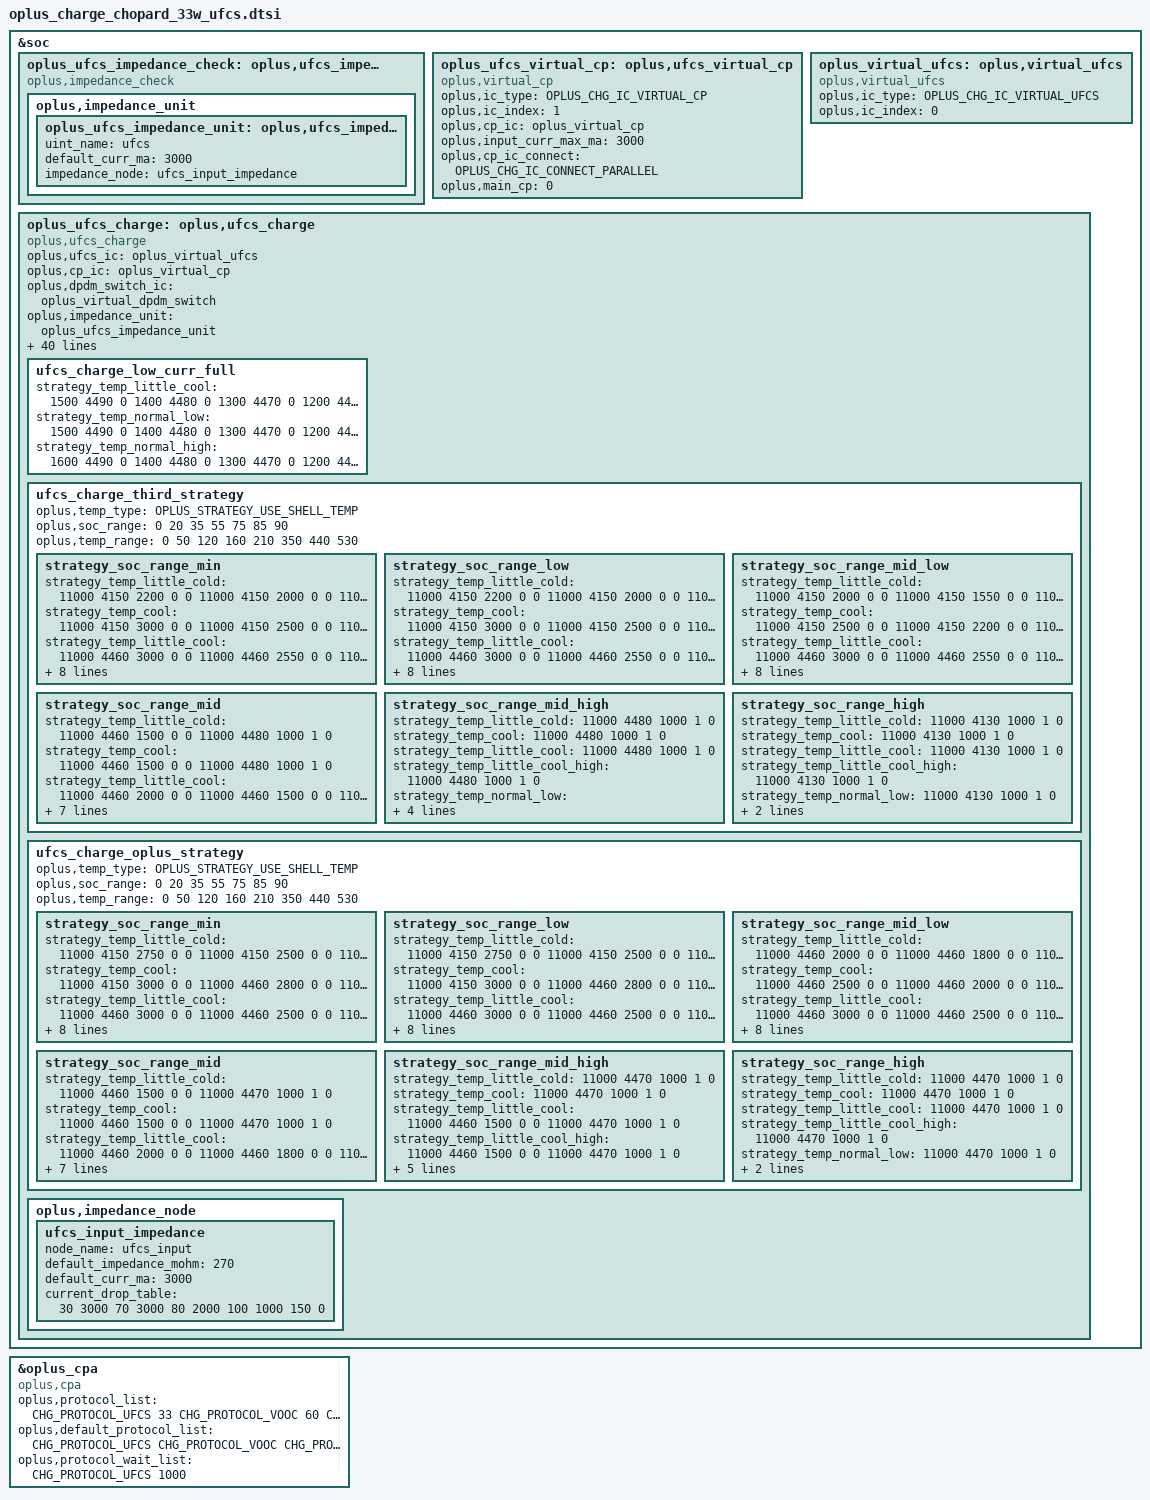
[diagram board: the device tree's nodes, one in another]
//ifdef OPLUS_FEATURE_CHG_BASIC

&soc {
	oplus_ufcs_impedance_check: oplus,ufcs_impedance_check {
		compatible = "oplus,impedance_check";

		oplus,impedance_unit {
			oplus_ufcs_impedance_unit: oplus,ufcs_impedance_unit {
				uint_name = "ufcs";
				default_curr_ma = <3000>;
				impedance_node = <&ufcs_input_impedance>;
			};
		};
	};

    oplus_ufcs_virtual_cp: oplus,ufcs_virtual_cp {
		compatible = "oplus,virtual_cp";

		oplus,ic_type = <OPLUS_CHG_IC_VIRTUAL_CP>;
		oplus,ic_index = <1>;

		oplus,cp_ic = <&oplus_virtual_cp>;
		oplus,input_curr_max_ma = <3000>;

		oplus,cp_ic_connect = <OPLUS_CHG_IC_CONNECT_PARALLEL>;
		oplus,main_cp = <0>;
	};

	oplus_virtual_ufcs: oplus,virtual_ufcs {
		compatible = "oplus,virtual_ufcs";

		oplus,ic_type = <OPLUS_CHG_IC_VIRTUAL_UFCS>;
		oplus,ic_index = <0>;
	};

	oplus_ufcs_charge: oplus,ufcs_charge {
		compatible = "oplus,ufcs_charge";
		oplus,ufcs_ic = <&oplus_virtual_ufcs>;
		oplus,cp_ic = <&oplus_virtual_cp>;
		oplus,dpdm_switch_ic = <&oplus_virtual_dpdm_switch>;

		oplus,impedance_unit = <&oplus_ufcs_impedance_unit>;

		oplus,target_vbus_mv = <11000>;
		oplus,curr_max_ma = <3000>;

		oplus,curr_table_type = <UFCS_CURR_CP_TABLE>;
		oplus,curve_strategy_name = "pps_ufcs_curve_v2";

		oplus,ufcs_warm_allow_vol = <4000>;
		oplus,ufcs_warm_allow_soc = <55>;
		oplus,ufcs_strategy_normal_current = <3000>;
		oplus,ufcs_over_high_or_low_current = <3000>;
		oplus,ufcs_timeout_third = <17562>;
		oplus,ufcs_timeout_oplus = <17562>;
		oplus,ufcs_ibat_over_third = <7000>;
		oplus,ufcs_ibat_over_oplus = <7000>;
		oplus,ufcs_full_cool_sw_vbat = <4470>;
		oplus,ufcs_full_normal_sw_vbat = <4520>;
		oplus,ufcs_full_normal_hw_vbat = <4530>;
		oplus,ufcs_full_ffc_vbat = <4485>;
		oplus,ufcs_full_warm_vbat = <4130>;
		oplus,ufcs_full_cool_sw_vbat_third = <4480>;
		oplus,ufcs_full_normal_sw_vbat_third= <4480>;
		oplus,ufcs_full_normal_hw_vbat_third = <4490>;
		oplus_spec,ufcs_high_soc = <86>;
		oplus,ufcs_current_change_timeout = <100>;
		oplus,ufcs_strategy_batt_high_temp = <410 420 430 400 410 420>;
		oplus,ufcs_strategy_high_current = <3000 2000 2000 3000 3000 3000>;
		oplus,ufcs_charge_strategy_soc = <0 20 35 55 75 85 90>;
		oplus,ufcs_charge_strategy_temp = <0 50 120 160 350 440 530>;
		oplus,ufcs_little_cool_high_temp = <210>;
		oplus,ufcs_low_curr_full_strategy_temp = <0 200 350 440>;

		oplus,plc_strategy-data = <&oplus_ufcs_step_strategy &third_ufcs_simple_strategy>;
		oplus,plc_strategy-names = "default", "third";

		oplus,temperature_strategy_name = "cgcl";
 		oplus,temperature_strategy_data = <OPLUS_STRATEGY_USE_SHELL_TEMP
 						0   410 4000 1 0
 						400 420 3000 2 0
						410 430 3000 3 1
 						420 440 2000 3 2>;

 		ufcs_charge_low_curr_full {
		strategy_temp_little_cool = <1500 4490 0
								1400 4480 0
								1300 4470 0
								1200 4460 0
								1100 4450 1>;
		strategy_temp_normal_low = <1500 4490 0
                                1400 4480 0
                                1300 4470 0
                                1200 4460 0
                                1100 4450 1>;
		strategy_temp_normal_high = <1600 4490 0
                                1400 4480 0
                                1300 4470 0
                                1200 4460 0
                                1100 4450 1>;
		};

		ufcs_charge_third_strategy {
			oplus,temp_type = <OPLUS_STRATEGY_USE_SHELL_TEMP>;
			oplus,soc_range = <0 20 35 55 75 85 90>;
			oplus,temp_range = <0 50 120 160 210 350 440 530>;

			strategy_soc_range_min {
				strategy_temp_little_cold =	<11000 4150 2200 0 0
								11000 4150 2000 0 0
								11000 4150 1550 0 0
								11000 4150 1500 0 0
								11000 4480 1000 1 0>;
				strategy_temp_cool =		<11000 4150 3000 0 0
								11000 4150 2500 0 0
								11000 4150 2200 0 0
								11000 4150 2000 0 0
								11000 4150 1500 0 0
								11000 4480 1000 1 0>;
				strategy_temp_little_cool =	<11000 4460 3000 0 0
								11000 4460 2550 0 0
								11000 4460 2500 0 0
								11000 4460 2000 0 0
								11000 4460 1500 0 0
								11000 4480 1000 1 0>;
				strategy_temp_little_cool_high = <11000 4460 3000 0 0
								11000 4460 2750 0 0
								11000 4460 2500 0 0
								11000 4460 2000 0 0
								11000 4460 1500 0 0
								11000 4480 1000 1 0>;
				strategy_temp_normal_low =	<11000 4460 3000 0 0
								11000 4460 2750 0 0
								11000 4460 2500 0 0
								11000 4460 2000 0 0
								11000 4460 1500 0 0
								11000 4480 1000 1 0>;
				strategy_temp_normal_high =	<11000 4440 3000 0 0
								11000 4440 2750 0 0
								11000 4440 2500 0 0
								11000 4440 2000 0 0
								11000 4440 1500 0 0
								11000 4460 1000 1 0>;
				strategy_temp_warm =		<11000 4100 1850 0 0
								11000 4100 1500 0 0
								11000 4120 1000 1 0>;
			};
			strategy_soc_range_low {
				strategy_temp_little_cold =	<11000 4150 2200 0 0
								11000 4150 2000 0 0
								11000 4480 1550 0 0
								11000 4480 1500 0 0
								11000 4480 1000 1 0>;
				strategy_temp_cool =		<11000 4150 3000 0 0
								11000 4150 2500 0 0
								11000 4480 2200 0 0
								11000 4480 2000 0 0
								11000 4480 1500 0 0
								11000 4480 1000 1 0>;
				strategy_temp_little_cool =	<11000 4460 3000 0 0
								11000 4460 2550 0 0
								11000 4460 2500 0 0
								11000 4460 2000 0 0
								11000 4460 1500 0 0
								11000 4480 1000 1 0>;
				strategy_temp_little_cool_high = <11000 4460 3000 0 0
								11000 4460 2750 0 0
								11000 4460 2500 0 0
								11000 4460 2000 0 0
								11000 4460 1500 0 0
								11000 4480 1000 1 0>;
				strategy_temp_normal_low =	<11000 4460 3000 0 0
								11000 4460 2750 0 0
								11000 4460 2500 0 0
								11000 4460 2000 0 0
								11000 4460 1500 0 0
								11000 4480 1000 1 0>;
				strategy_temp_normal_high =	<11000 4440 3000 0 0
								11000 4440 2750 0 0
								11000 4440 2500 0 0
								11000 4440 2000 0 0
								11000 4440 1500 0 0
								11000 4460 1000 1 0>;
				strategy_temp_warm =		<11000 4100 1850 0 0
								11000 4100 1500 0 0
								11000 4120 1000 1 0>;
			};
			strategy_soc_range_mid_low {
				strategy_temp_little_cold =	<11000 4150 2000 0 0
								11000 4150 1550 0 0
								11000 4150 1500 0 0
								11000 4480 1000 1 0>;
				strategy_temp_cool =		<11000 4150 2500 0 0
								11000 4150 2200 0 0
								11000 4150 2000 0 0
								11000 4150 1500 0 0
								11000 4480 1000 1 0>;
				strategy_temp_little_cool =	<11000 4460 3000 0 0
								11000 4460 2550 0 0
								11000 4460 2500 0 0
								11000 4460 2000 0 0
								11000 4460 1500 0 0
								11000 4480 1000 1 0>;
				strategy_temp_little_cool_high = <11000 4460 3000 0 0
								11000 4460 2750 0 0
								11000 4460 2500 0 0
								11000 4460 2000 0 0
								11000 4460 1500 0 0
								11000 4480 1000 1 0>;
				strategy_temp_normal_low =	<11000 4460 3000 0 0
								11000 4460 2750 0 0
								11000 4460 2500 0 0
								11000 4460 2000 0 0
								11000 4460 1500 0 0
								11000 4480 1000 1 0>;
				strategy_temp_normal_high =	<11000 4440 3000 0 0
								11000 4440 2750 0 0
								11000 4440 2500 0 0
								11000 4440 2000 0 0
								11000 4440 1500 0 0
								11000 4460 1000 1 0>;
				strategy_temp_warm =		<11000 4100 1850 0 0
								11000 4100 1500 0 0
								11000 4120 1000 1 0>;
			};
			strategy_soc_range_mid {
				strategy_temp_little_cold =	<11000 4460 1500 0 0
								11000 4480 1000 1 0>;
				strategy_temp_cool =		<11000 4460 1500 0 0
								11000 4480 1000 1 0>;
				strategy_temp_little_cool =	<11000 4460 2000 0 0
								11000 4460 1500 0 0
								11000 4480 1000 1 0>;
				strategy_temp_little_cool_high = <11000 4460 2000 0 0
								11000 4460 1500 0 0
								11000 4480 1000 1 0>;
				strategy_temp_normal_low =	<11000 4460 2000 0 0
								11000 4460 1500 0 0
								11000 4480 1000 1 0>;
				strategy_temp_normal_high =	<11000 4440 2500 0 0
								11000 4440 2000 0 0
								11000 4440 1500 0 0
								11000 4460 1000 1 0>;
				strategy_temp_warm =		<11000 4130 1000 1 0>;
			};
			strategy_soc_range_mid_high {
				strategy_temp_little_cold =	<11000 4480 1000 1 0>;
				strategy_temp_cool =		<11000 4480 1000 1 0>;
				strategy_temp_little_cool =	<11000 4480 1000 1 0>;
				strategy_temp_little_cool_high = <11000 4480 1000 1 0>;
				strategy_temp_normal_low =	<11000 4460 1500 0 0
								11000 4480 1000 1 0>;
				strategy_temp_normal_high =	<11000 4400 1500 0 0
								11000 4460 1000 1 0>;
				strategy_temp_warm =		<11000 4130 1000 1 0>;
			};
			strategy_soc_range_high {
				strategy_temp_little_cold =	<11000 4130 1000 1 0>;
				strategy_temp_cool =		<11000 4130 1000 1 0>;
				strategy_temp_little_cool =	<11000 4130 1000 1 0>;
				strategy_temp_little_cool_high = <11000 4130 1000 1 0>;
				strategy_temp_normal_low =	<11000 4130 1000 1 0>;
				strategy_temp_normal_high =	<11000 4130 1000 1 0>;
				strategy_temp_warm =		<11000 4130 1000 1 0>;
			};
		};

		ufcs_charge_oplus_strategy {
			oplus,temp_type = <OPLUS_STRATEGY_USE_SHELL_TEMP>;
			oplus,soc_range = <0 20 35 55 75 85 90>;
			oplus,temp_range = <0 50 120 160 210 350 440 530>;
			strategy_soc_range_min {
				strategy_temp_little_cold =	<11000 4150 2750 0 0
								11000 4150 2500 0 0
								11000 4460 2250 0 0
								11000 4460 2000 0 0
								11000 4460 1800 0 0
								11000 4460 1500 0 0
								11000 4470 1000 1 0>;
				strategy_temp_cool =		<11000 4150 3000 0 0
								11000 4460 2800 0 0
								11000 4460 2500 0 0
								11000 4460 2000 0 0
								11000 4460 1800 0 0
								11000 4460 1500 0 0
								11000 4470 1000 1 0>;
				strategy_temp_little_cool =	<11000 4460 3000 0 0
								11000 4460 2500 0 0
								11000 4460 2000 0 0
								11000 4460 1800 0 0
								11000 4460 1500 0 0
								11000 4470 1000 1 0>;
				strategy_temp_little_cool_high = <11000 4460 3000 0 0
								11000 4460 2500 0 0
								11000 4460 2000 0 0
								11000 4460 1800 0 0
								11000 4460 1500 0 0
								11000 4470 1000 1 0>;
				strategy_temp_normal_low =	<11000 4460 3000 0 0
								11000 4460 2500 0 0
								11000 4460 2000 0 0
								11000 4460 1500 0 0
								11000 4470 1000 1 0>;
				strategy_temp_normal_high =	<11000 4460 3000 0 0
								11000 4460 2500 0 0
								11000 4460 2000 0 0
								11000 4460 1500 0 0
								11000 4470 1000 1 0>;
				strategy_temp_warm =		<11000 4120 1300 0 0
								11000 4130 1000 1 0>;
			};
			strategy_soc_range_low {
				strategy_temp_little_cold =	<11000 4150 2750 0 0
								11000 4150 2500 0 0
								11000 4460 2250 0 0
								11000 4460 2000 0 0
								11000 4460 1800 0 0
								11000 4460 1500 0 0
								11000 4470 1000 1 0>;
				strategy_temp_cool =		<11000 4150 3000 0 0
								11000 4460 2800 0 0
								11000 4460 2500 0 0
								11000 4460 2000 0 0
								11000 4460 1800 0 0
								11000 4460 1500 0 0
								11000 4470 1000 1 0>;
				strategy_temp_little_cool =	<11000 4460 3000 0 0
								11000 4460 2500 0 0
								11000 4460 2000 0 0
								11000 4460 1800 0 0
								11000 4460 1500 0 0
								11000 4470 1000 1 0>;
				strategy_temp_little_cool_high = <11000 4460 3000 0 0
								11000 4460 2500 0 0
								11000 4460 2000 0 0
								11000 4460 1800 0 0
								11000 4460 1500 0 0
								11000 4470 1000 1 0>;
				strategy_temp_normal_low =	<11000 4460 3000 0 0
								11000 4460 2500 0 0
								11000 4460 2000 0 0
								11000 4460 1500 0 0
								11000 4470 1000 1 0>;
				strategy_temp_normal_high =	<11000 4460 3000 0 0
								11000 4460 2500 0 0
								11000 4460 2000 0 0
								11000 4460 1500 0 0
								11000 4470 1000 1 0>;
				strategy_temp_warm =		<11000 4120 1300 0 0
								11000 4130 1000 1 0>;
			};
			strategy_soc_range_mid_low {
				strategy_temp_little_cold =	<11000 4460 2000 0 0
								11000 4460 1800 0 0
								11000 4460 1500 0 0
								11000 4470 1000 1 0>;
				strategy_temp_cool =		<11000 4460 2500 0 0
								11000 4460 2000 0 0
								11000 4460 1800 0 0
								11000 4460 1500 0 0
								11000 4470 1000 1 0>;
				strategy_temp_little_cool =	<11000 4460 3000 0 0
								11000 4460 2500 0 0
								11000 4460 2000 0 0
								11000 4460 1800 0 0
								11000 4460 1500 0 0
								11000 4470 1000 1 0>;
				strategy_temp_little_cool_high = <11000 4460 3000 0 0
								11000 4460 2500 0 0
								11000 4460 2000 0 0
								11000 4460 1800 0 0
								11000 4460 1500 0 0
								11000 4470 1000 1 0>;
				strategy_temp_normal_low =	<11000 4460 3000 0 0
								11000 4460 2500 0 0
								11000 4460 2000 0 0
								11000 4460 1500 0 0
								11000 4470 1000 1 0>;
				strategy_temp_normal_high =	<11000 4460 3000 0 0
								11000 4460 2500 0 0
								11000 4460 2000 0 0
								11000 4460 1500 0 0
								11000 4470 1000 1 0>;
				strategy_temp_warm =		<11000 4120 1300 0 0
								11000 4130 1000 1 0>;
			};
			strategy_soc_range_mid {
				strategy_temp_little_cold =	<11000 4460 1500 0 0
								11000 4470 1000 1 0>;
				strategy_temp_cool =		<11000 4460 1500 0 0
								11000 4470 1000 1 0>;
				strategy_temp_little_cool =	<11000 4460 2000 0 0
								11000 4460 1800 0 0
								11000 4460 1500 0 0
								11000 4470 1000 1 0>;
				strategy_temp_little_cool_high = <11000 4460 2000 0 0
								11000 4460 1800 0 0
								11000 4460 1500 0 0
								11000 4470 1000 1 0>;
				strategy_temp_normal_low =	<11000 4460 2000 0 0
								11000 4460 1500 0 0
								11000 4470 1000 1 0>;
				strategy_temp_normal_high =	<11000 4460 2500 0 0
								11000 4460 2000 0 0
								11000 4460 1500 0 0
								11000 4470 1000 1 0>;
				strategy_temp_warm =		<11000 4130 1000 1 0>;
			};
			strategy_soc_range_mid_high {
				strategy_temp_little_cold =	<11000 4470 1000 1 0>;
				strategy_temp_cool =		<11000 4470 1000 1 0>;
				strategy_temp_little_cool =	<11000 4460 1500 0 0
								11000 4470 1000 1 0>;
				strategy_temp_little_cool_high = <11000 4460 1500 0 0
								11000 4470 1000 1 0>;
				strategy_temp_normal_low =	<11000 4460 1500 0 0
								11000 4470 1000 1 0>;
				strategy_temp_normal_high =	<11000 4460 1500 0 0
								11000 4470 1000 1 0>;
				strategy_temp_warm =		<11000 4130 1000 1 0>;
			};
			strategy_soc_range_high {
				strategy_temp_little_cold =	<11000 4470 1000 1 0>;
				strategy_temp_cool =		<11000 4470 1000 1 0>;
				strategy_temp_little_cool =	<11000 4470 1000 1 0>;
				strategy_temp_little_cool_high = <11000 4470 1000 1 0>;
				strategy_temp_normal_low =	<11000 4470 1000 1 0>;
				strategy_temp_normal_high =	<11000 4470 1000 1 0>;
				strategy_temp_warm =		<11000 4130 1000 1 0>;
			};
		};
		oplus,impedance_node {
			ufcs_input_impedance: ufcs_input_impedance {
				node_name = "ufcs_input";
				default_impedance_mohm = <270>;
				default_curr_ma = <3000>;
				current_drop_table = <
					30  3000
					70  3000
					80  2000
					100 1000
					150 0
				>;
			};
		};
	};
};

&oplus_cpa {
	compatible = "oplus,cpa";
	oplus,protocol_list = <CHG_PROTOCOL_UFCS 33
			       CHG_PROTOCOL_VOOC  60
			       CHG_PROTOCOL_PPS  45
			       CHG_PROTOCOL_PD 15>;
	oplus,default_protocol_list = <CHG_PROTOCOL_UFCS
					CHG_PROTOCOL_VOOC
					CHG_PROTOCOL_PPS
					CHG_PROTOCOL_PD>;
	oplus,protocol_wait_list = <CHG_PROTOCOL_UFCS 1000>;
};
//#endif OPLUS_FEATURE_CHG_BASIC
